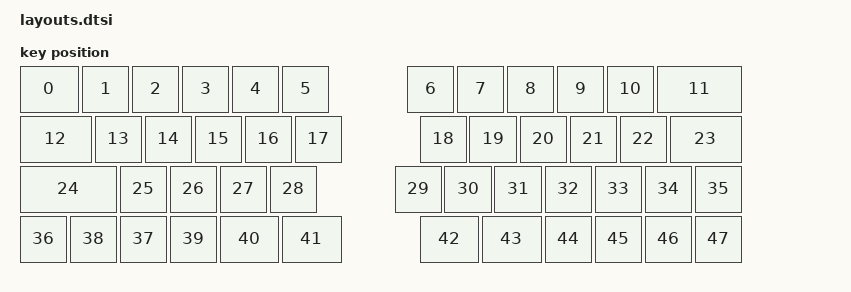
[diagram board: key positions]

#include <physical_layouts.dtsi>
/ {
    physical_layout0: physical_layout0 {
        compatible = "zmk,physical-layout";
        display-name = "Layout";
        keys
            = <&key_physical_attrs 125 100 (-50) 0 0 0 0>
			,<&key_physical_attrs 100 100 75 0 0 0 0>
			,<&key_physical_attrs 100 100 175 0 0 0 0>
			,<&key_physical_attrs 100 100 275 0 0 0 0>
			,<&key_physical_attrs 100 100 375 0 0 0 0>
			,<&key_physical_attrs 100 100 475 0 0 0 0>
			,<&key_physical_attrs 100 100 725 0 0 0 0>
			,<&key_physical_attrs 100 100 825 0 0 0 0>
			,<&key_physical_attrs 100 100 925 0 0 0 0>
			,<&key_physical_attrs 100 100 1025 0 0 0 0>
			,<&key_physical_attrs 100 100 1125 0 0 0 0>
			,<&key_physical_attrs 175 100 1225 0 0 0 0>
			,<&key_physical_attrs 150 100 (-50) 100 0 0 0>
			,<&key_physical_attrs 100 100 100 100 0 0 0>
			,<&key_physical_attrs 100 100 200 100 0 0 0>
			,<&key_physical_attrs 100 100 300 100 0 0 0>
			,<&key_physical_attrs 100 100 400 100 0 0 0>
			,<&key_physical_attrs 100 100 500 100 0 0 0>
			,<&key_physical_attrs 100 100 750 100 0 0 0>
			,<&key_physical_attrs 100 100 850 100 0 0 0>
			,<&key_physical_attrs 100 100 950 100 0 0 0>
			,<&key_physical_attrs 100 100 1050 100 0 0 0>
			,<&key_physical_attrs 100 100 1150 100 0 0 0>
			,<&key_physical_attrs 150 100 1250 100 0 0 0>
			,<&key_physical_attrs 200 100 (-50) 200 0 0 0>
			,<&key_physical_attrs 100 100 150 200 0 0 0>
			,<&key_physical_attrs 100 100 250 200 0 0 0>
			,<&key_physical_attrs 100 100 350 200 0 0 0>
			,<&key_physical_attrs 100 100 450 200 0 0 0>
			,<&key_physical_attrs 100 100 700 200 0 0 0>
			,<&key_physical_attrs 100 100 800 200 0 0 0>
			,<&key_physical_attrs 100 100 900 200 0 0 0>
			,<&key_physical_attrs 100 100 1000 200 0 0 0>
			,<&key_physical_attrs 100 100 1100 200 0 0 0>
			,<&key_physical_attrs 100 100 1200 200 0 0 0>
			,<&key_physical_attrs 100 100 1300 200 0 0 0>
			,<&key_physical_attrs 100 100 (-50) 300 0 0 0>
			,<&key_physical_attrs 100 100 150 300 0 0 0>
			,<&key_physical_attrs 100 100 50 300 0 0 0>
			,<&key_physical_attrs 100 100 250 300 0 0 0>
			,<&key_physical_attrs 125 100 350 300 0 0 0>
			,<&key_physical_attrs 125 100 475 300 0 0 0>
			,<&key_physical_attrs 125 100 750 300 0 0 0>
			,<&key_physical_attrs 125 100 875 300 0 0 0>
			,<&key_physical_attrs 100 100 1000 300 0 0 0>
			,<&key_physical_attrs 100 100 1100 300 0 0 0>
			,<&key_physical_attrs 100 100 1200 300 0 0 0>
			,<&key_physical_attrs 100 100 1300 300 0 0 0>
            ;
    };
};
    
